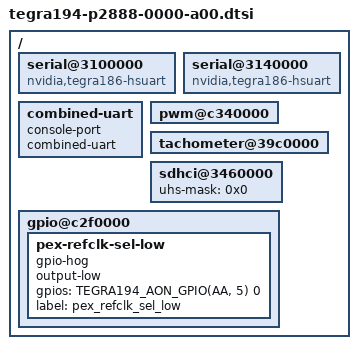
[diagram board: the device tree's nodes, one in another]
/*
 * T194 E3360-1099 common DTSI file.
 *
 * Copyright (c) 2017, NVIDIA CORPORATION.  All rights reserved.
 *
 * This program is free software; you can redistribute it and/or modify
 * it under the terms of the GNU General Public License as published by
 * the Free Software Foundation; version 2 of the License.
 *
 * This program is distributed in the hope that it will be useful, but WITHOUT
 * ANY WARRANTY; without even the implied warranty of MERCHANTABILITY or
 * FITNESS FOR A PARTICULAR PURPOSE.  See the GNU General Public License for
 * more details.
 */

#include <t19x-common-modules/tegra194-cvm-p2888-0000-a00.dtsi>
#include "tegra194-eeprom-manager-p2888-0000.dtsi"
#include <t19x-common-platforms/tegra194-platforms-eqos.dtsi>
#include "tegra194-powermon-p2888.dtsi"

/ {
	serial@3100000 {
		compatible = "nvidia,tegra186-hsuart";
		status = "okay";
	};

	serial@3140000 {
		compatible = "nvidia,tegra186-hsuart";
		status = "okay";
	};

	combined-uart {
		console-port;
		combined-uart;
		status = "okay";
	};

	pwm@c340000 {
		status = "okay";
	};

	tachometer@39c0000 {
		status = "okay";
	};

	sdhci@3460000 {
		uhs-mask = <0x0>;
		status = "okay";
	};

	gpio@c2f0000 {
		pex-refclk-sel-low {
			gpio-hog;
			output-low;
			gpios = <TEGRA194_AON_GPIO(AA, 5) 0>;
			label = "pex_refclk_sel_low";
			status = "okay";
		};
	};
};
